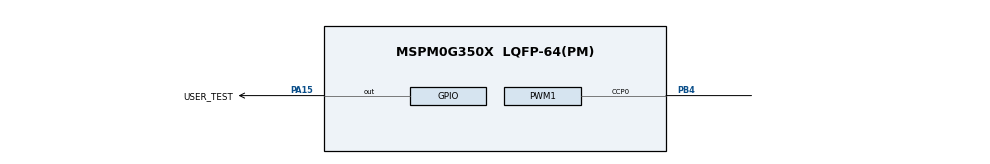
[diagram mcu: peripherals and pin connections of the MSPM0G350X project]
// @cliArgs --device "MSPM0G350X" --package "LQFP-64(PM)" --part "Default"
// @cliArgs --board /ti/boards/LP_MSPM0G3507 --rtos nortos

/**
 * Import the modules used in this configuration.
 */
const GPIO   = scripting.addModule("/ti/driverlib/GPIO", {}, false);
const GPIO1  = GPIO.addInstance();
const PWM    = scripting.addModule("/ti/driverlib/PWM", {}, false);
const PWM1   = PWM.addInstance();
const SYSCTL = scripting.addModule("/ti/driverlib/SYSCTL");

/**
 * Write custom configuration values to the imported modules.
 */
GPIO1.$name                                 = "GPIO_LEDS";
GPIO1.associatedPins.create(2);
GPIO1.associatedPins[0].$name               = "USER_LED_1";
GPIO1.associatedPins[0].assignedPort        = "PORTA";
GPIO1.associatedPins[0].assignedPin         = "0";
GPIO1.associatedPins[0].initialValue        = "SET";
GPIO1.associatedPins[1].assignedPort        = "PORTA";
GPIO1.associatedPins[1].assignedPortSegment = "Lower";
GPIO1.associatedPins[1].$name               = "USER_TEST";
GPIO1.associatedPins[1].pin.$assign         = "PA15";
GPIO1.associatedPins[1].initialValue        = "SET";

const gate7  = system.clockTree["MFCLKGATE"];
gate7.enable = true;

PWM1.$name                          = "PWM_0";
PWM1.dbRiseDelayTimerCount          = 50;
PWM1.dbFallDelayTimerCount          = 25;
PWM1.ccIndex                        = [0];
PWM1.clockSource                    = "MFCLK";
PWM1.clockPrescale                  = 4;
PWM1.timerCount                     = 8191;
PWM1.enableShadowLoad               = true;
PWM1.interrupts                     = ["CC0_DN_EVENT"];
PWM1.peripheral.$assign             = "TIMA1";
PWM1.peripheral.ccp0Pin.$assign     = "PB4";
PWM1.PWM_CHANNEL_0.$name            = "ti_driverlib_pwm_PWMTimerCC0";
PWM1.PWM_CHANNEL_0.ccValue          = 799;
PWM1.PWM_CHANNEL_0.shadowUpdateMode = "ZERO_EVT";

const Board = scripting.addModule("/ti/driverlib/Board", {}, false);

SYSCTL.MFCLKEn     = true;
SYSCTL.forceDefaultClkConfig = true;
SYSCTL.clockTreeEn  = true;
